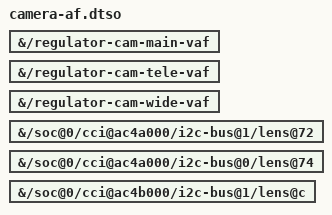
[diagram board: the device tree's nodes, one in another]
// SPDX-License-Identifier: MIT
/*
 * Bring-up (CAMERA-PLAN.md, AF steps): the three focus actuators and their
 * VAF load switches. Apply after camera.dtso and camera-main.dtso. The
 * sensors' lens-focus links are in the base DT: with a lens enabled, the
 * media graph waits for its driver, so ak7375 and lc898217xc must load
 * with the other camera modules (or be blacklisted together with them).
 * The base DT describes a SEMCO main/tele module (LC898217XC at 0x72/0x74).
 */
/dts-v1/;
/plugin/;

&{/regulator-cam-main-vaf} {
	status = "okay";
};

&{/regulator-cam-tele-vaf} {
	status = "okay";
};

&{/regulator-cam-wide-vaf} {
	status = "okay";
};

&{/soc@0/cci@ac4a000/i2c-bus@1/lens@72} {
	status = "okay";
};

&{/soc@0/cci@ac4a000/i2c-bus@0/lens@74} {
	status = "okay";
};

&{/soc@0/cci@ac4b000/i2c-bus@1/lens@c} {
	status = "okay";
};
